VERSION ""

NS_ :

BS_:

BU_: VCU RMT AUTO

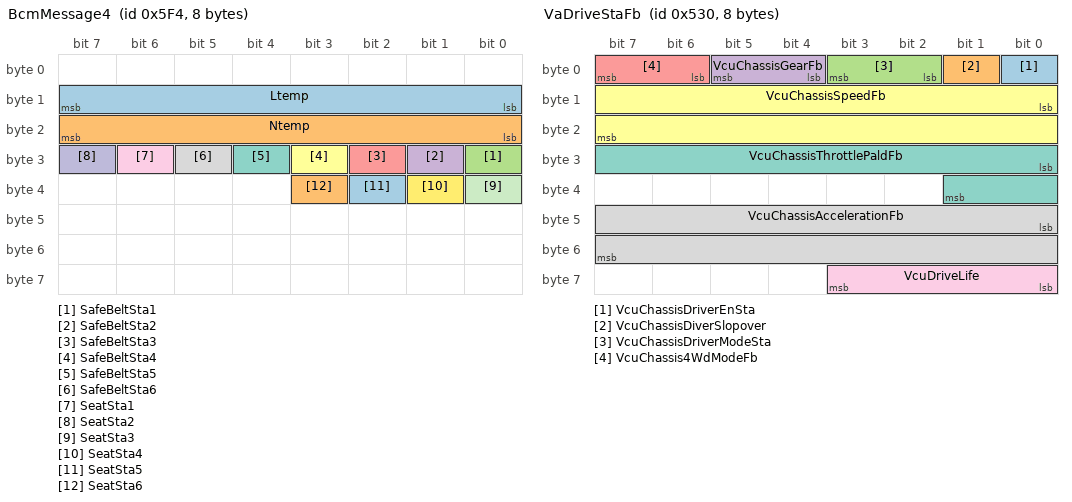
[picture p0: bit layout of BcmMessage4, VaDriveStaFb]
BO_ 1524 BcmMessage4: 8 VCU
 SG_ Ltemp : 8|8@1+ (1,-40) [-40|215] "℃"    RMT ,   AUTO
 SG_ Ntemp : 16|8@1+ (1,-40) [-40|215] "℃"    RMT ,   AUTO
 SG_ SafeBeltSta1 : 24|1@1+ (1,0) [0|1] ""    RMT ,   AUTO
 SG_ SafeBeltSta2 : 25|1@1+ (1,0) [0|1] ""    RMT ,   AUTO
 SG_ SafeBeltSta3 : 26|1@1+ (1,0) [0|1] ""    RMT ,   AUTO
 SG_ SafeBeltSta4 : 27|1@1+ (1,0) [0|1] ""    RMT ,   AUTO
 SG_ SafeBeltSta5 : 28|1@1+ (1,0) [0|1] ""    RMT ,   AUTO
 SG_ SafeBeltSta6 : 29|1@1+ (1,0) [0|1] ""    RMT ,   AUTO
 SG_ SeatSta1 : 30|1@1+ (1,0) [0|1] ""    RMT ,   AUTO
 SG_ SeatSta2 : 31|1@1+ (1,0) [0|1] ""    RMT ,   AUTO
 SG_ SeatSta3 : 32|1@1+ (1,0) [0|1] ""    RMT ,   AUTO
 SG_ SeatSta4 : 33|1@1+ (1,0) [0|1] ""    RMT ,   AUTO
 SG_ SeatSta5 : 34|1@1+ (1,0) [0|1] ""    RMT ,   AUTO
 SG_ SeatSta6 : 35|1@1+ (1,0) [0|1] ""    RMT ,   AUTO

BO_ 1525 BcmMessage5: 8 VCU
 SG_ AdVVin1 : 32|8@1+ (1,0) [0|255] ""    RMT ,   AUTO
 SG_ AdVVin2 : 40|8@1+ (1,0) [0|255] ""    RMT ,   AUTO

BO_ 1328 VaDriveStaFb: 8 VCU
 SG_ VcuChassisDriverEnSta : 0|1@1+ (1,0) [0|1] ""    RMT ,   AUTO
 SG_ VcuChassisDiverSlopover : 1|1@1+ (1,0) [0|1] ""    RMT ,   AUTO
 SG_ VcuChassisDriverModeSta : 2|2@1+ (1,0) [0|3] ""    RMT ,   AUTO
 SG_ VcuChassisGearFb : 4|2@1+ (1,0) [0|3] ""    RMT ,   AUTO
 SG_ VcuChassis4WdModeFb : 6|2@1+ (1,0) [0|2] ""    RMT ,   AUTO
 SG_ VcuChassisSpeedFb : 8|16@1- (0.01,0) [-50|50] "m/s"    RMT ,   AUTO
 SG_ VcuChassisThrottlePaldFb : 24|10@1+ (0.1,0) [0|100] "%"    RMT ,   AUTO
 SG_ VcuChassisAccelerationFb : 40|16@1- (0.01,0) [-20|20] "m/s2"    RMT ,   AUTO
 SG_ VcuDriveLife : 56|4@1+ (1,0) [0|15] ""    RMT ,   AUTO

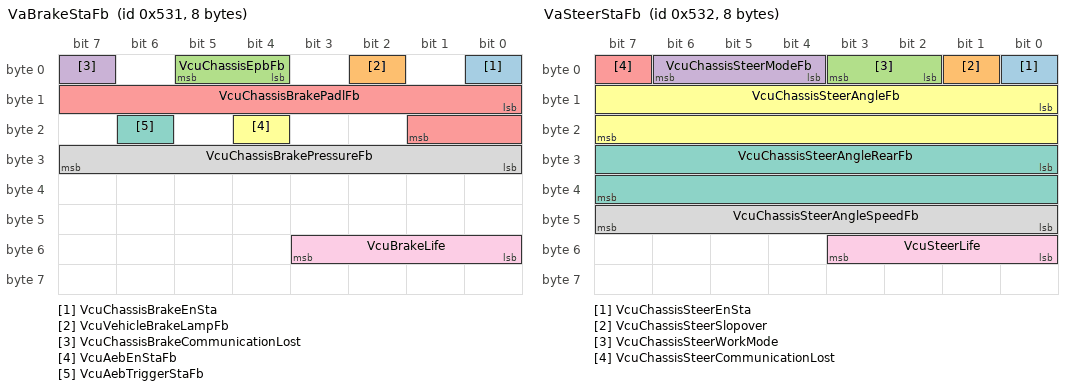
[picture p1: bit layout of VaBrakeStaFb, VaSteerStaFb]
BO_ 1329 VaBrakeStaFb: 8 VCU
 SG_ VcuChassisBrakeEnSta : 0|1@1+ (1,0) [0|1] ""    RMT ,   AUTO
 SG_ VcuVehicleBrakeLampFb : 2|1@1+ (1,0) [0|1] ""    RMT ,   AUTO
 SG_ VcuChassisEpbFb : 4|2@1+ (1,0) [0|3] ""    RMT ,   AUTO
 SG_ VcuChassisBrakeCommunicationLost : 7|1@1+ (1,0) [0|1] ""    RMT ,   AUTO
 SG_ VcuChassisBrakePadlFb : 8|10@1+ (0.1,0) [0|100] "%"    RMT ,   AUTO
 SG_ VcuAebEnStaFb : 20|1@1+ (1,0) [0|1] ""    RMT ,   AUTO
 SG_ VcuAebTriggerStaFb : 22|1@1+ (1,0) [0|1] ""    RMT ,   AUTO
 SG_ VcuChassisBrakePressureFb : 24|8@1+ (1,0) [0|100] "bar"    RMT ,   AUTO
 SG_ VcuBrakeLife : 48|4@1+ (1,0) [0|15] ""    RMT ,   AUTO

BO_ 1330 VaSteerStaFb: 8 VCU
 SG_ VcuChassisSteerEnSta : 0|1@1+ (1,0) [0|1] ""    RMT ,   AUTO
 SG_ VcuChassisSteerSlopover : 1|1@1+ (1,0) [0|1] ""    RMT ,   AUTO
 SG_ VcuChassisSteerWorkMode : 2|2@1+ (1,0) [0|2] ""    RMT ,   AUTO
 SG_ VcuChassisSteerModeFb : 4|3@1+ (1,0) [0|4] ""    RMT ,   AUTO
 SG_ VcuChassisSteerCommunicationLost : 7|1@1+ (1,0) [0|1] ""    RMT ,   AUTO
 SG_ VcuChassisSteerAngleFb : 8|16@1- (1,0) [-500|500] "deg"    RMT ,   AUTO
 SG_ VcuChassisSteerAngleRearFb : 24|16@1- (1,0) [-500|500] "deg"    RMT ,   AUTO
 SG_ VcuChassisSteerAngleSpeedFb : 40|8@1+ (2,0) [0|500] "deg/s"    RMT ,   AUTO
 SG_ VcuSteerLife : 48|4@1+ (1,0) [0|15] ""    RMT ,   AUTO

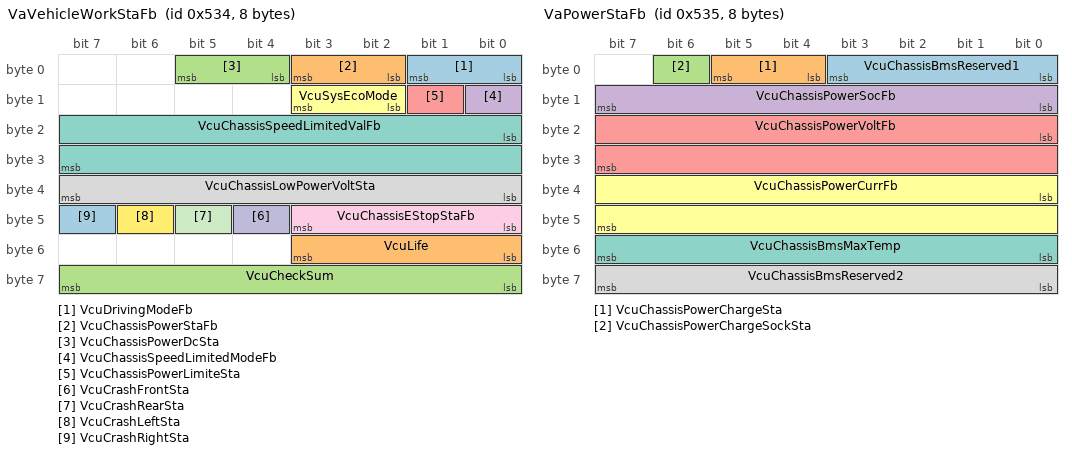
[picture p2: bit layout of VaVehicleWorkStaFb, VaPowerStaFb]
BO_ 1332 VaVehicleWorkStaFb: 8 VCU
 SG_ VcuDrivingModeFb : 0|2@1+ (1,0) [0|3] ""    RMT ,   AUTO
 SG_ VcuChassisPowerStaFb : 2|2@1+ (1,0) [0|3] ""    RMT ,   AUTO
 SG_ VcuChassisPowerDcSta : 4|2@1+ (1,0) [0|2] ""    RMT ,   AUTO
 SG_ VcuChassisSpeedLimitedModeFb : 8|1@1+ (1,0) [0|1] ""    RMT ,   AUTO
 SG_ VcuChassisPowerLimiteSta : 9|1@1+ (1,0) [0|1] ""    RMT ,   AUTO
 SG_ VcuSysEcoMode : 10|2@1+ (1,0) [0|2] ""    RMT ,   AUTO
 SG_ VcuChassisSpeedLimitedValFb : 16|16@1+ (0.1,0) [0|50] "m/s"    RMT ,   AUTO
 SG_ VcuChassisLowPowerVoltSta : 32|8@1+ (0.1,0) [0|25] "V"    RMT ,   AUTO
 SG_ VcuChassisEStopStaFb : 40|4@1+ (1,0) [0|3] ""    RMT ,   AUTO
 SG_ VcuCrashFrontSta : 44|1@1+ (1,0) [0|1] ""    RMT ,   AUTO
 SG_ VcuCrashRearSta : 45|1@1+ (1,0) [0|1] ""    RMT ,   AUTO
 SG_ VcuCrashLeftSta : 46|1@1+ (1,0) [0|1] ""    RMT ,   AUTO
 SG_ VcuCrashRightSta : 47|1@1+ (1,0) [0|1] ""    RMT ,   AUTO
 SG_ VcuLife : 48|4@1+ (1,0) [0|15] ""    RMT ,   AUTO
 SG_ VcuCheckSum : 56|8@1+ (1,0) [0|255] ""    RMT ,   AUTO

BO_ 1333 VaPowerStaFb: 8 VCU
 SG_ VcuChassisBmsReserved1 : 0|4@1+ (1,0) [0|15] ""    RMT ,   AUTO
 SG_ VcuChassisPowerChargeSta : 4|2@1+ (1,0) [0|2] ""    RMT ,   AUTO
 SG_ VcuChassisPowerChargeSockSta : 6|1@1+ (1,0) [0|1] ""    RMT ,   AUTO
 SG_ VcuChassisPowerSocFb : 8|8@1+ (1,0) [0|100] "%"    RMT ,   AUTO
 SG_ VcuChassisPowerVoltFb : 16|16@1+ (0.1,0) [0|1000] "V"    RMT ,   AUTO
 SG_ VcuChassisPowerCurrFb : 32|16@1+ (0.1,-1000) [-1000|1000] "A"    RMT ,   AUTO
 SG_ VcuChassisBmsMaxTemp : 48|8@1+ (1,-40) [-40|80] "℃"    RMT ,   AUTO
 SG_ VcuChassisBmsReserved2 : 56|8@1+ (1,0) [0|255] ""    RMT ,   AUTO

BO_ 1334 VaVehicleStaFb: 8 VCU
 SG_ VcuVehiclePosLampFb : 0|1@1+ (1,0) [0|1] ""    RMT ,   AUTO
 SG_ VcuVehicleHeadLampFb : 1|1@1+ (1,0) [0|1] ""    RMT ,   AUTO
 SG_ VcuVehicleLeftLampFb : 2|1@1+ (1,0) [0|1] ""    RMT ,   AUTO
 SG_ VcuVehicleRightLampFb : 3|1@1+ (1,0) [0|1] ""    RMT ,   AUTO
 SG_ VcuVehicleHighBeamFb : 4|1@1+ (1,0) [0|1] ""    RMT ,   AUTO
 SG_ VcuVehicleFogLampFb : 5|1@1+ (1,0) [0|1] ""    RMT ,   AUTO
 SG_ VcuVehicleHazardWarLampFb : 6|1@1+ (1,0) [0|1] ""    RMT ,   AUTO
 SG_ VcuVehicleBodyLampFb : 7|1@1+ (1,0) [0|1] ""    RMT ,   AUTO
 SG_ VcuVehicleReadLampFb : 8|1@1+ (1,0) [0|1] ""    RMT ,   AUTO
 SG_ AcuVehicleWindowFb : 9|4@1+ (1,0) [0|6] ""    RMT ,   AUTO
 SG_ VcuVehicleDoorStaFb : 16|4@1+ (1,0) [0|6] ""    RMT ,   AUTO
 SG_ VcuVehicleWipersStaFb : 20|2@1+ (1,0) [0|3] ""    RMT ,   AUTO
 SG_ VcuVehicleSafetyBelt1 : 24|2@1+ (1,0) [0|3] ""    RMT ,   AUTO
 SG_ VcuVehicleSafetyBelt2 : 26|2@1+ (1,0) [0|3] ""    RMT ,   AUTO
 SG_ VcuVehicleSafetyBelt3 : 28|2@1+ (1,0) [0|3] ""    RMT ,   AUTO
 SG_ VcuVehicleSafetyBelt4 : 30|2@1+ (1,0) [0|3] ""    RMT ,   AUTO
 SG_ VcuVehicleSafetyBelt5 : 32|2@1+ (1,0) [0|3] ""    AUTO
 SG_ VcuVehicleSafetyBelt6 : 34|2@1+ (1,0) [0|3] ""    AUTO
 SG_ VcuVehicleReserveWarning : 40|16@1+ (1,0) [0|65535] ""    AUTO
 SG_ VcuVehicleDisplaySpeed : 56|8@1+ (1,0) [0|240] "Km/h"    AUTO

BO_ 1335 VaVehicleFltSta: 8 VCU
 SG_ VcuSysMotorOverTempSta : 0|1@1+ (1,0) [0|1] ""    RMT ,   AUTO
 SG_ VcuSysBmsOverTempSta : 1|1@1+ (1,0) [0|1] ""    RMT ,   AUTO
 SG_ VcuSysBrakeOverTempSta : 2|1@1+ (1,0) [0|1] ""    RMT ,   AUTO
 SG_ VcuSysSteerOverTempSta : 3|1@1+ (1,0) [0|1] ""    RMT ,   AUTO
 SG_ VcuSysUnderVolt : 4|1@1+ (1,0) [0|1] ""    RMT ,   AUTO
 SG_ VcuSysFlt : 8|4@1+ (1,0) [0|4] ""    RMT ,   AUTO
 SG_ VcuSysBrakeFlt : 12|4@1+ (1,0) [0|4] ""    RMT ,   AUTO
 SG_ VcuSysParkingFlt : 16|4@1+ (1,0) [0|4] ""    RMT ,   AUTO
 SG_ VcuSysSteerFrontFlt : 20|4@1+ (1,0) [0|4] ""    RMT ,   AUTO
 SG_ VcuSysSteerBackFlt : 24|4@1+ (1,0) [0|4] ""    RMT ,   AUTO
 SG_ VcuSysMotorLfFlt : 28|4@1+ (1,0) [0|4] ""    RMT ,   AUTO
 SG_ VcuSysMotorRfFlt : 32|4@1+ (1,0) [0|4] ""    RMT ,   AUTO
 SG_ VcuSysMotorLrFlt : 36|4@1+ (1,0) [0|4] ""    RMT ,   AUTO
 SG_ VcuSysMotorRrFlt : 40|4@1+ (1,0) [0|4] ""    RMT ,   AUTO
 SG_ VcuSysBmsFlt : 44|4@1+ (1,0) [0|4] ""    RMT ,   AUTO
 SG_ VcuSysDcFlt : 48|2@1+ (1,0) [0|4] ""    RMT ,   AUTO
 SG_ VcuSysDoorFlt : 50|2@1+ (1,0) [0|3] ""    RMT ,   AUTO
 SG_ VcuSysDpmFlt : 52|2@1+ (1,0) [0|3] ""    RMT ,   AUTO
 SG_ VcuSysBcmFlt : 54|2@1+ (1,0) [0|3] ""    RMT ,   AUTO
 SG_ VcuVehicleFltLevel : 56|4@1+ (1,0) [0|4] ""    RMT ,   AUTO
 SG_ VcuSysFltReserve1 : 60|4@1+ (1,0) [0|4] ""    RMT ,   AUTO

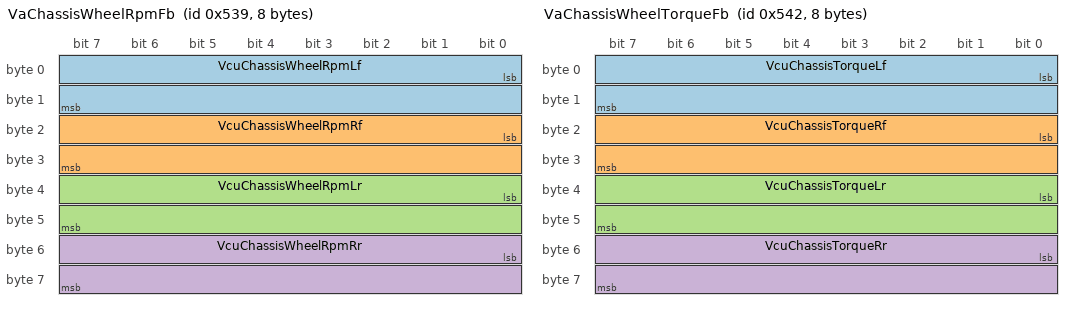
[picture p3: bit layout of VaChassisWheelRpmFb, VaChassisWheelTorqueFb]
BO_ 1337 VaChassisWheelRpmFb: 8 VCU
 SG_ VcuChassisWheelRpmLf : 0|16@1- (1,0) [-2000|2000] "rpm"    RMT ,   AUTO
 SG_ VcuChassisWheelRpmRf : 16|16@1- (1,0) [-2000|2000] "rpm"    RMT ,   AUTO
 SG_ VcuChassisWheelRpmLr : 32|16@1- (1,0) [-2000|2000] "rpm"    RMT ,   AUTO
 SG_ VcuChassisWheelRpmRr : 48|16@1- (1,0) [-2000|2000] "rpm"    RMT ,   AUTO

BO_ 1346 VaChassisWheelTorqueFb: 8 VCU
 SG_ VcuChassisTorqueLf : 0|16@1- (0.1,0) [-200|200] "Nm"    RMT ,   AUTO
 SG_ VcuChassisTorqueRf : 16|16@1- (0.1,0) [-200|200] "Nm"    RMT ,   AUTO
 SG_ VcuChassisTorqueLr : 32|16@1- (0.1,0) [-200|200] "Nm"    RMT ,   AUTO
 SG_ VcuChassisTorqueRr : 48|16@1- (0.1,0) [-200|200] "Nm"    RMT ,   AUTO

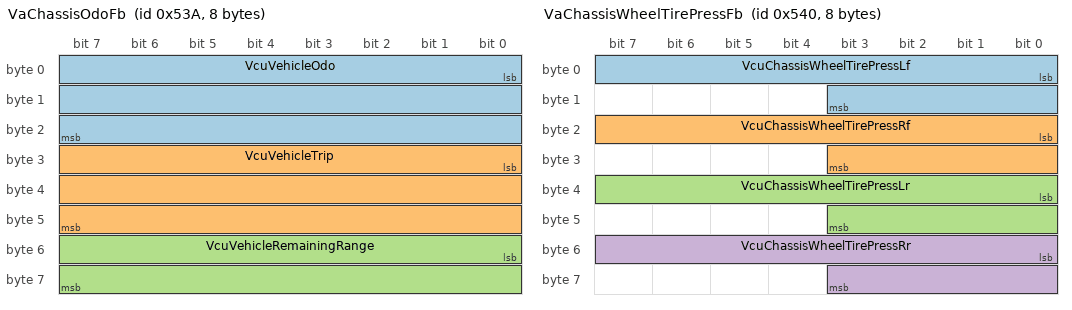
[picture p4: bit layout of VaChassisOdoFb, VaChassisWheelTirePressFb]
BO_ 1338 VaChassisOdoFb: 8 VCU
 SG_ VcuVehicleOdo : 0|24@1+ (1,0) [0|16777215] "km"    RMT ,   AUTO
 SG_ VcuVehicleTrip : 24|24@1+ (0.01,0) [0|167772.15] "km"    RMT ,   AUTO
 SG_ VcuVehicleRemainingRange : 48|16@1+ (1,0) [0|1000] "km"    RMT ,   AUTO

BO_ 1344 VaChassisWheelTirePressFb: 8 VCU
 SG_ VcuChassisWheelTirePressLf : 0|12@1+ (0.01,0) [0|20] "bar"    RMT ,   AUTO
 SG_ VcuChassisWheelTirePressRf : 16|12@1+ (0.01,0) [0|20] "bar"    RMT ,   AUTO
 SG_ VcuChassisWheelTirePressLr : 32|12@1+ (0.01,0) [0|20] "bar"    RMT ,   AUTO
 SG_ VcuChassisWheelTirePressRr : 48|12@1+ (0.01,0) [0|20] "bar"    RMT ,   AUTO

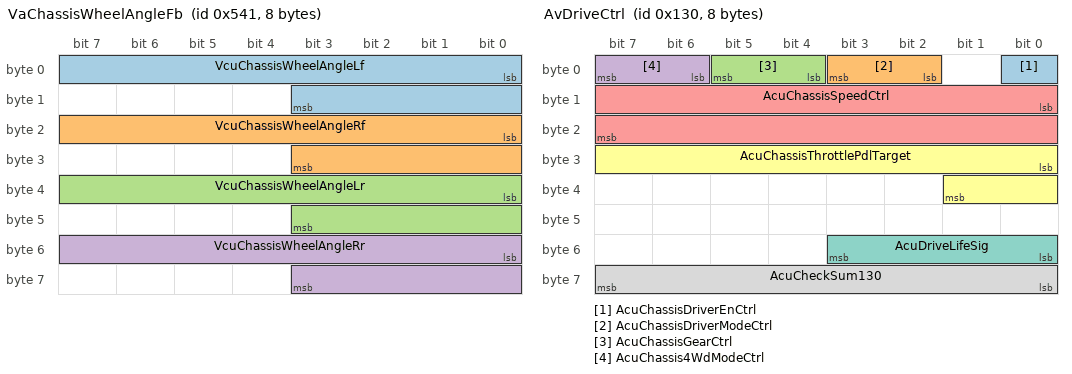
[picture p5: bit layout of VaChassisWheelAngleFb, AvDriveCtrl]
BO_ 1345 VaChassisWheelAngleFb: 8 VCU
 SG_ VcuChassisWheelAngleLf : 0|12@1- (0.1,0) [-90|90] "deg"    RMT ,   AUTO
 SG_ VcuChassisWheelAngleRf : 16|12@1- (0.1,0) [-90|90] "deg"    RMT ,   AUTO
 SG_ VcuChassisWheelAngleLr : 32|12@1- (0.1,0) [-90|90] "deg"    RMT ,   AUTO
 SG_ VcuChassisWheelAngleRr : 48|12@1- (0.1,0) [-90|90] "deg"    RMT ,   AUTO

BO_ 304 AvDriveCtrl: 8 RMT
 SG_ AcuChassisDriverEnCtrl : 0|1@1+ (1,0) [0|1] ""   VCU
 SG_ AcuChassisDriverModeCtrl : 2|2@1+ (1,0) [0|3] ""   VCU
 SG_ AcuChassisGearCtrl : 4|2@1+ (1,0) [0|3] ""   VCU
 SG_ AcuChassis4WdModeCtrl : 6|2@1+ (1,0) [0|2] ""   VCU
 SG_ AcuChassisSpeedCtrl : 8|16@1+ (0.01,0) [0|50] "m/s"   VCU
 SG_ AcuChassisThrottlePdlTarget : 24|10@1+ (0.1,0) [0|100] "%"   VCU
 SG_ AcuDriveLifeSig : 48|4@1+ (1,0) [0|15] ""   VCU
 SG_ AcuCheckSum130 : 56|8@1+ (1,0) [0|255] ""   VCU

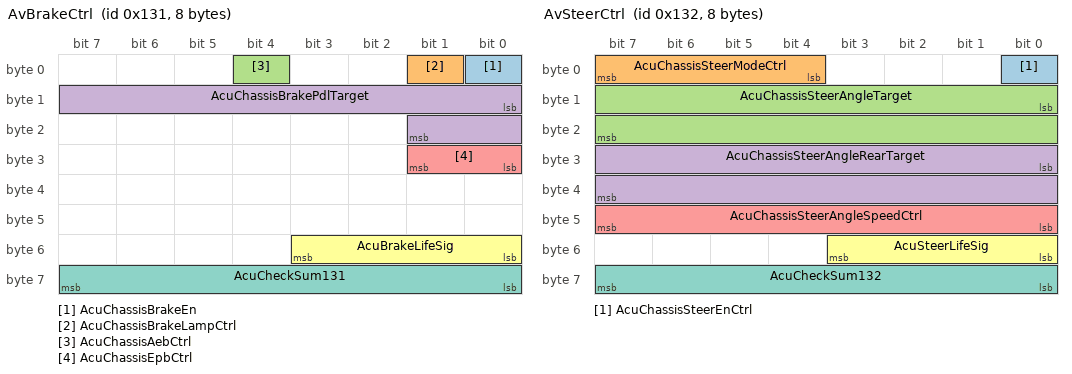
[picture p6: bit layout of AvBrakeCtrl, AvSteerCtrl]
BO_ 305 AvBrakeCtrl: 8 RMT
 SG_ AcuChassisBrakeEn : 0|1@1+ (1,0) [0|1] ""   VCU
 SG_ AcuChassisBrakeLampCtrl : 1|1@1+ (1,0) [0|1] ""   VCU
 SG_ AcuChassisAebCtrl : 4|1@1+ (1,0) [0|1] ""   VCU
 SG_ AcuChassisBrakePdlTarget : 8|10@1+ (0.1,0) [0|100] "%"   VCU
 SG_ AcuChassisEpbCtrl : 24|2@1+ (1,0) [0|2] ""   VCU
 SG_ AcuBrakeLifeSig : 48|4@1+ (1,0) [0|15] ""   VCU
 SG_ AcuCheckSum131 : 56|8@1+ (1,0) [0|255] ""   VCU

BO_ 306 AvSteerCtrl: 8 RMT
 SG_ AcuChassisSteerEnCtrl : 0|1@1+ (1,0) [0|1] ""   VCU
 SG_ AcuChassisSteerModeCtrl : 4|4@1+ (1,0) [0|4] ""   VCU
 SG_ AcuChassisSteerAngleTarget : 8|16@1- (1,0) [-500|500] "deg"   VCU
 SG_ AcuChassisSteerAngleRearTarget : 24|16@1- (1,0) [-500|500] "deg"   VCU
 SG_ AcuChassisSteerAngleSpeedCtrl : 40|8@1+ (2,0) [0|500] "deg/s"   VCU
 SG_ AcuSteerLifeSig : 48|4@1+ (1,0) [0|15] ""   VCU
 SG_ AcuCheckSum132 : 56|8@1+ (1,0) [0|255] ""   VCU

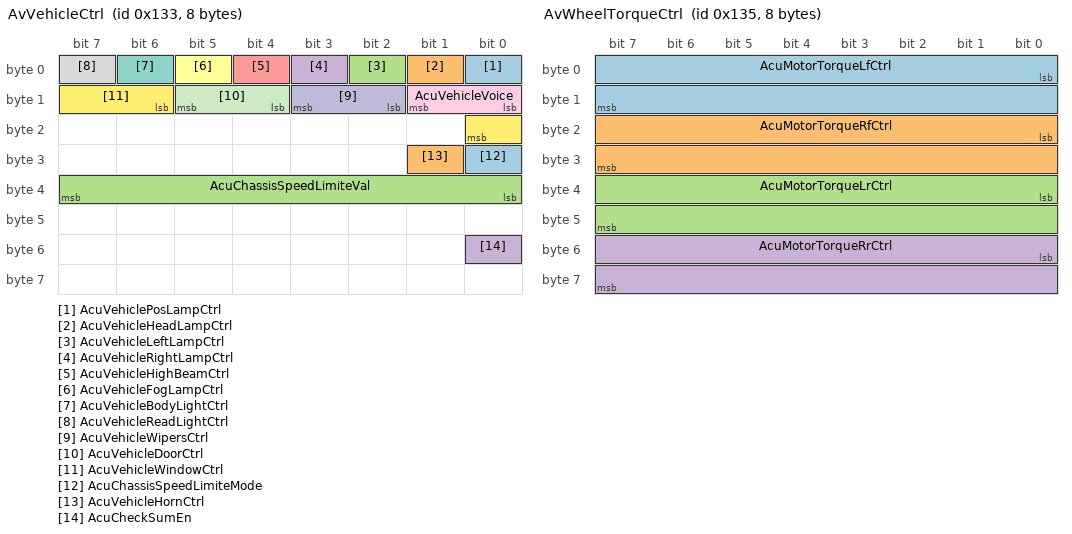
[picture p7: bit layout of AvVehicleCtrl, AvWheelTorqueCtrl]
BO_ 307 AvVehicleCtrl: 8 RMT
 SG_ AcuVehiclePosLampCtrl : 0|1@1+ (1,0) [0|1] ""   VCU
 SG_ AcuVehicleHeadLampCtrl : 1|1@1+ (1,0) [0|1] ""   VCU
 SG_ AcuVehicleLeftLampCtrl : 2|1@1+ (1,0) [0|1] ""   VCU
 SG_ AcuVehicleRightLampCtrl : 3|1@1+ (1,0) [0|1] ""   VCU
 SG_ AcuVehicleHighBeamCtrl : 4|1@1+ (1,0) [0|1] ""   VCU
 SG_ AcuVehicleFogLampCtrl : 5|1@1+ (1,0) [0|1] ""   VCU
 SG_ AcuVehicleBodyLightCtrl : 6|1@1+ (1,0) [0|1] ""   VCU
 SG_ AcuVehicleReadLightCtrl : 7|1@1+ (1,0) [0|1] ""   VCU
 SG_ AcuVehicleVoice : 8|2@1+ (1,0) [0|3] ""   VCU
 SG_ AcuVehicleWipersCtrl : 10|2@1+ (1,0) [0|3] ""   VCU
 SG_ AcuVehicleDoorCtrl : 12|2@1+ (1,0) [0|2] ""   VCU
 SG_ AcuVehicleWindowCtrl : 14|3@1+ (1,0) [0|2] ""   VCU
 SG_ AcuChassisSpeedLimiteMode : 24|1@1+ (1,0) [0|1] ""   VCU
 SG_ AcuVehicleHornCtrl : 25|1@1+ (1,0) [0|1] ""   VCU
 SG_ AcuChassisSpeedLimiteVal : 32|8@1+ (0.1,0) [1|20] "m/s"   VCU
 SG_ AcuCheckSumEn : 48|1@1+ (1,0) [0|1] ""   VCU

BO_ 309 AvWheelTorqueCtrl: 8 RMT
 SG_ AcuMotorTorqueLfCtrl : 0|16@1- (0.1,0) [-200|200] "Nm"   VCU
 SG_ AcuMotorTorqueRfCtrl : 16|16@1- (0.1,0) [-200|200] "Nm"   VCU
 SG_ AcuMotorTorqueLrCtrl : 32|16@1- (0.1,0) [-200|200] "Nm"   VCU
 SG_ AcuMotorTorqueRrCtrl : 48|16@1- (0.1,0) [-200|200] "Nm"   VCU

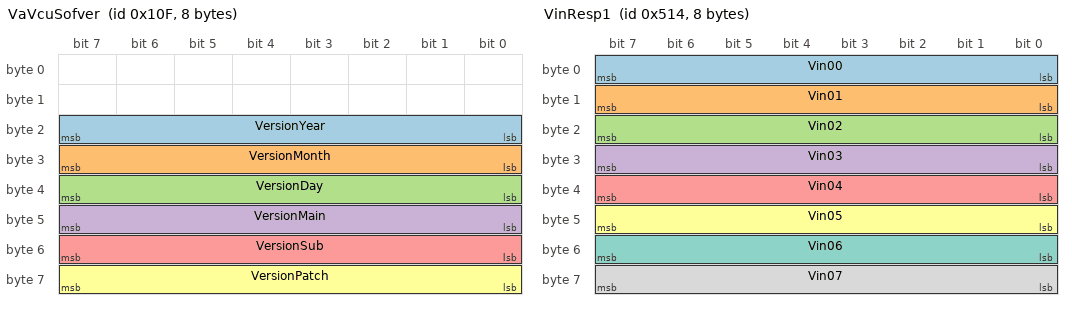
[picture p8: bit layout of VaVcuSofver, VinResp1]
BO_ 271 VaVcuSofver: 8 VCU
 SG_ VersionYear : 16|8@1+ (1,0) [0|255] ""    RMT ,   AUTO
 SG_ VersionMonth : 24|8@1+ (1,0) [0|255] ""    RMT ,   AUTO
 SG_ VersionDay : 32|8@1+ (1,0) [0|255] ""    RMT ,   AUTO
 SG_ VersionMain : 40|8@1+ (1,0) [0|255] ""    RMT ,   AUTO
 SG_ VersionSub : 48|8@1+ (1,0) [0|255] ""    RMT ,   AUTO
 SG_ VersionPatch : 56|8@1+ (1,0) [0|255] ""    RMT ,   AUTO

BO_ 1300 VinResp1: 8 VCU
 SG_ Vin00 : 0|8@1+ (1,0) [0|255] ""    RMT ,   AUTO
 SG_ Vin01 : 8|8@1+ (1,0) [0|255] ""    RMT ,   AUTO
 SG_ Vin02 : 16|8@1+ (1,0) [0|255] ""    RMT ,   AUTO
 SG_ Vin03 : 24|8@1+ (1,0) [0|255] ""    RMT ,   AUTO
 SG_ Vin04 : 32|8@1+ (1,0) [0|255] ""    RMT ,   AUTO
 SG_ Vin05 : 40|8@1+ (1,0) [0|255] ""    RMT ,   AUTO
 SG_ Vin06 : 48|8@1+ (1,0) [0|255] ""    RMT ,   AUTO
 SG_ Vin07 : 56|8@1+ (1,0) [0|255] ""    RMT ,   AUTO

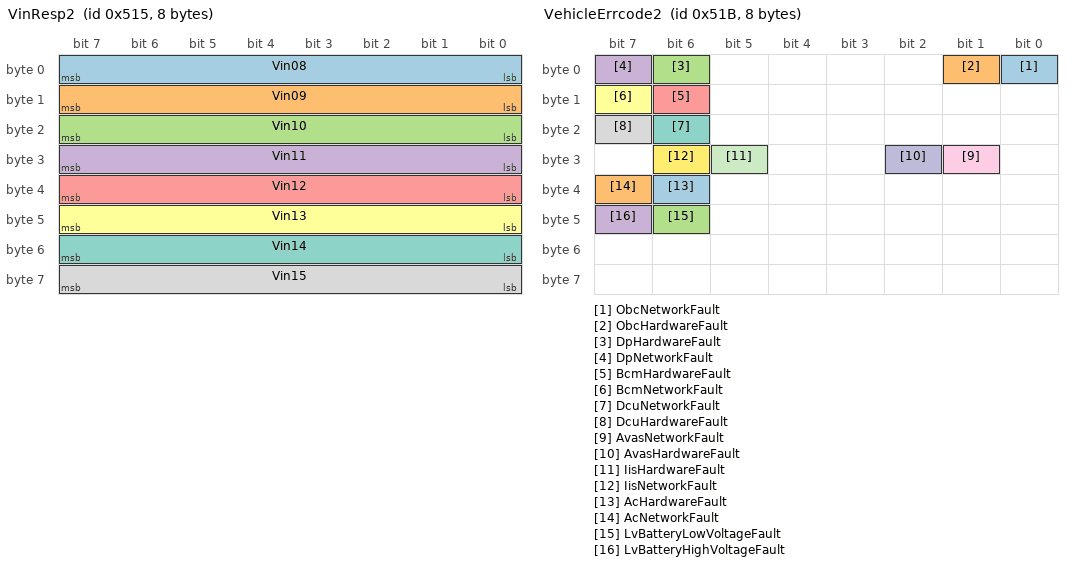
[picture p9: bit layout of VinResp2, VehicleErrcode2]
BO_ 1301 VinResp2: 8 VCU
 SG_ Vin08 : 0|8@1+ (1,0) [0|255] ""    RMT ,   AUTO
 SG_ Vin09 : 8|8@1+ (1,0) [0|255] ""    RMT ,   AUTO
 SG_ Vin10 : 16|8@1+ (1,0) [0|255] ""    RMT ,   AUTO
 SG_ Vin11 : 24|8@1+ (1,0) [0|255] ""    RMT ,   AUTO
 SG_ Vin12 : 32|8@1+ (1,0) [0|255] ""    RMT ,   AUTO
 SG_ Vin13 : 40|8@1+ (1,0) [0|255] ""    RMT ,   AUTO
 SG_ Vin14 : 48|8@1+ (1,0) [0|255] ""    RMT ,   AUTO
 SG_ Vin15 : 56|8@1+ (1,0) [0|255] ""    RMT ,   AUTO

BO_ 1302 VinResp3: 8 VCU
 SG_ Vin16 : 0|8@1+ (1,0) [0|255] ""    RMT ,   AUTO

BO_ 928 AutoMessage: 8 RMT
 SG_ AutoDriveMode : 0|8@1+ (1,0) [0|255] ""    VCU ,   AUTO
 SG_ AutoHeartbeat : 56|8@1+ (1,0) [0|255] ""    VCU ,   AUTO

BO_ 944 RemoteMessage: 8 AUTO
 SG_ RemoteDriveMode : 0|8@1+ (1,0) [0|255] ""   VCU,  RMT
 SG_ RemoteHeartbeat : 56|8@1+ (1,0) [0|255] ""   VCU,  RMT

BO_ 1339 VcuTransfer: 8 VCU
 SG_ AcOutTemp : 40|8@1- (1,-40) [-40|215] "℃"    RMT ,   AUTO
 SG_ AcInTemp : 48|8@1- (1,-40) [-40|215] "℃"    RMT ,   AUTO

BO_ 1306 VehicleErrcode1: 8 VCU
 SG_ FlmcHardwareFault : 0|1@1+ (1,0) [0|1] ""    RMT ,   AUTO
 SG_ FlmcTemFault : 1|1@1+ (1,0) [0|1] ""    RMT ,   AUTO
 SG_ FlmTemFault : 2|1@1+ (1,0) [0|1] ""    RMT ,   AUTO
 SG_ RlmcHardwareFault : 3|1@1+ (1,0) [0|1] ""    RMT ,   AUTO
 SG_ RlmcTemFault : 4|1@1+ (1,0) [0|1] ""    RMT ,   AUTO
 SG_ RlmTemFault : 5|1@1+ (1,0) [0|1] ""    RMT ,   AUTO
 SG_ FrmcHardwareFault : 6|1@1+ (1,0) [0|1] ""    RMT ,   AUTO
 SG_ FrmcTemFault : 7|1@1+ (1,0) [0|1] ""    RMT ,   AUTO
 SG_ FrmTemFault : 8|1@1+ (1,0) [0|1] ""    RMT ,   AUTO
 SG_ RrmcHardwareFault : 9|1@1+ (1,0) [0|1] ""    RMT ,   AUTO
 SG_ RrmcTemFault : 10|1@1+ (1,0) [0|1] ""    RMT ,   AUTO
 SG_ RrmTemFault : 11|1@1+ (1,0) [0|1] ""    RMT ,   AUTO
 SG_ FlmcNetworkFault : 12|1@1+ (1,0) [0|1] ""    RMT ,   AUTO
 SG_ FrmcNetworkFault : 13|1@1+ (1,0) [0|1] ""    RMT ,   AUTO
 SG_ RlmcNetworkFault : 14|1@1+ (1,0) [0|1] ""    RMT ,   AUTO
 SG_ RrmcNetworkFault : 15|1@1+ (1,0) [0|1] ""    RMT ,   AUTO
 SG_ FsteerHardwareFault : 16|1@1+ (1,0) [0|1] ""    RMT ,   AUTO
 SG_ RsteerHardwareFault : 17|1@1+ (1,0) [0|1] ""    RMT ,   AUTO
 SG_ FsteerNetworkFault : 18|1@1+ (1,0) [0|1] ""    RMT ,   AUTO
 SG_ RsteerNetworkFault : 19|1@1+ (1,0) [0|1] ""    RMT ,   AUTO
 SG_ BrakeHardwareFault : 20|1@1+ (1,0) [0|1] ""    RMT ,   AUTO
 SG_ BrakeHighTemFault : 21|1@1+ (1,0) [0|1] ""    RMT ,   AUTO
 SG_ BrakeLuidLevelLow : 22|1@1+ (1,0) [0|1] ""    RMT ,   AUTO
 SG_ BrakeNetworkFault : 23|1@1+ (1,0) [0|1] ""    RMT ,   AUTO
 SG_ ParkHardwareFault : 24|1@1+ (1,0) [0|1] ""    RMT ,   AUTO
 SG_ ParkNetworkFault : 25|1@1+ (1,0) [0|1] ""    RMT ,   AUTO
 SG_ RcuNetworkFault : 26|1@1+ (1,0) [0|1] ""    RMT ,   AUTO
 SG_ RcuWeakSignal : 27|1@1+ (1,0) [0|1] ""    RMT ,   AUTO
 SG_ RcuElecLowAlarm : 28|1@1+ (1,0) [0|1] ""    RMT ,   AUTO
 SG_ BmsNetworkFault : 31|1@1+ (1,0) [0|1] ""    RMT ,   AUTO
 SG_ BmsInsulationfault : 32|1@1+ (1,0) [0|1] ""    RMT ,   AUTO
 SG_ BmsOcvCell : 33|1@1+ (1,0) [0|1] ""    RMT ,   AUTO
 SG_ BmsOdvCell : 34|1@1+ (1,0) [0|1] ""    RMT ,   AUTO
 SG_ BmsOcvBatt : 35|1@1+ (1,0) [0|1] ""    RMT ,   AUTO
 SG_ BmsOdvBatt : 36|1@1+ (1,0) [0|1] ""    RMT ,   AUTO
 SG_ BmsCellVoltDiff : 37|1@1+ (1,0) [0|1] ""    RMT ,   AUTO
 SG_ BmsTemph : 38|1@1+ (1,0) [0|1] ""    RMT ,   AUTO
 SG_ BmsTemphl : 39|1@1+ (1,0) [0|1] ""    RMT ,   AUTO
 SG_ BmsTemphDiff : 40|1@1+ (1,0) [0|1] ""    RMT ,   AUTO
 SG_ BmsWarchgOvercurrent : 41|1@1+ (1,0) [0|1] ""    RMT ,   AUTO
 SG_ BmsSoch : 42|1@1+ (1,0) [0|1] ""    RMT ,   AUTO
 SG_ BmsSocl : 43|1@1+ (1,0) [0|1] ""    RMT ,   AUTO
 SG_ BmsTimeOfHeatingTooLong : 44|1@1+ (1,0) [0|1] ""    RMT ,   AUTO
 SG_ BmsSocBreak : 45|1@1+ (1,0) [0|1] ""    RMT ,   AUTO
 SG_ BmsDisCharOverCur : 46|1@1+ (1,0) [0|1] ""    RMT ,   AUTO
 SG_ BmsCharOverCurSlow : 47|1@1+ (1,0) [0|1] ""    RMT ,   AUTO
 SG_ BmsfastCharOverCur : 48|1@1+ (1,0) [0|1] ""    RMT ,   AUTO
 SG_ BmsAlmSenseCell : 49|1@1+ (1,0) [0|1] ""    RMT ,   AUTO
 SG_ BmsAlmSenseTemp : 50|1@1+ (1,0) [0|1] ""    RMT ,   AUTO
 SG_ BmsAlmSenseCurr : 51|1@1+ (1,0) [0|1] ""    RMT ,   AUTO
 SG_ BmsHvil : 52|1@1+ (1,0) [0|1] ""    RMT ,   AUTO
 SG_ BmsWarIncanFault : 53|1@1+ (1,0) [0|1] ""    RMT ,   AUTO
 SG_ BmsLstComWithobc : 54|1@1+ (1,0) [0|1] ""    RMT ,   AUTO
 SG_ BmsLstComWithVcu : 55|1@1+ (1,0) [0|1] ""    RMT ,   AUTO
 SG_ BmsPrechargerFault : 56|1@1+ (1,0) [0|1] ""    RMT ,   AUTO
 SG_ BmsposRelayconglutination : 57|1@1+ (1,0) [0|1] ""    RMT ,   AUTO
 SG_ BmsNegRelayConglutination : 58|1@1+ (1,0) [0|1] ""    RMT ,   AUTO
 SG_ DcdcHighTemAlarm : 61|1@1+ (1,0) [0|1] "" Vector__XXX
 SG_ DcdcHardwareFault : 62|1@1+ (1,0) [0|1] ""    RMT ,   AUTO
 SG_ DcdcNetworkFault : 63|1@1+ (1,0) [0|1] ""    RMT ,   AUTO

BO_ 1307 VehicleErrcode2: 8 VCU
 SG_ ObcNetworkFault : 0|1@1+ (1,0) [0|1] ""    RMT ,   AUTO
 SG_ ObcHardwareFault : 1|1@1+ (1,0) [0|1] ""    RMT ,   AUTO
 SG_ DpHardwareFault : 6|1@1+ (1,0) [0|1] ""    RMT ,   AUTO
 SG_ DpNetworkFault : 7|1@1+ (1,0) [0|1] ""    RMT ,   AUTO
 SG_ BcmHardwareFault : 14|1@1+ (1,0) [0|1] ""    RMT ,   AUTO
 SG_ BcmNetworkFault : 15|1@1+ (1,0) [0|1] ""    RMT ,   AUTO
 SG_ DcuNetworkFault : 22|1@1+ (1,0) [0|1] ""    RMT ,   AUTO
 SG_ DcuHardwareFault : 23|1@1+ (1,0) [0|1] ""    RMT ,   AUTO
 SG_ AvasNetworkFault : 25|1@1+ (1,0) [0|1] ""    RMT ,   AUTO
 SG_ AvasHardwareFault : 26|1@1+ (1,0) [0|1] ""    RMT ,   AUTO
 SG_ IisHardwareFault : 29|1@1+ (1,0) [0|1] ""    RMT ,   AUTO
 SG_ IisNetworkFault : 30|1@1+ (1,0) [0|1] ""    RMT ,   AUTO
 SG_ AcHardwareFault : 38|1@1+ (1,0) [0|1] ""    RMT ,   AUTO
 SG_ AcNetworkFault : 39|1@1+ (1,0) [0|1] ""    RMT ,   AUTO
 SG_ LvBatteryLowVoltageFault : 46|1@1+ (1,0) [0|1] ""    RMT ,   AUTO
 SG_ LvBatteryHighVoltageFault : 47|1@1+ (1,0) [0|1] ""    RMT ,   AUTO

BO_ 1308 HistoricalVehiclefailures1: 8 VCU
 SG_ FlmcHardwareFault : 0|1@1+ (1,0) [0|1] ""    RMT ,   AUTO
 SG_ FlmcTemFault : 1|1@1+ (1,0) [0|1] ""    RMT ,   AUTO
 SG_ FlmTemFault : 2|1@1+ (1,0) [0|1] ""    RMT ,   AUTO
 SG_ RlmcHardwareFault : 3|1@1+ (1,0) [0|1] ""    RMT ,   AUTO
 SG_ RlmcTemFault : 4|1@1+ (1,0) [0|1] ""    RMT ,   AUTO
 SG_ RlmTemFault : 5|1@1+ (1,0) [0|1] ""    RMT ,   AUTO
 SG_ FrmcHardwareFault : 6|1@1+ (1,0) [0|1] ""    RMT ,   AUTO
 SG_ FrmcTemFault : 7|1@1+ (1,0) [0|1] ""    RMT ,   AUTO
 SG_ FrmTemFault : 8|1@1+ (1,0) [0|1] ""    RMT ,   AUTO
 SG_ RrmcHardwareFault : 9|1@1+ (1,0) [0|1] ""    RMT ,   AUTO
 SG_ RrmcTemFault : 10|1@1+ (1,0) [0|1] ""    RMT ,   AUTO
 SG_ RrmTemFault : 11|1@1+ (1,0) [0|1] ""    RMT ,   AUTO
 SG_ FlmcNetworkFault : 12|1@1+ (1,0) [0|1] ""    RMT ,   AUTO
 SG_ FrmcNetworkFault : 13|1@1+ (1,0) [0|1] ""    RMT ,   AUTO
 SG_ RlmcNetworkFault : 14|1@1+ (1,0) [0|1] ""    RMT ,   AUTO
 SG_ RrmcNetworkFault : 15|1@1+ (1,0) [0|1] ""    RMT ,   AUTO
 SG_ FsteerHardwareFault : 16|1@1+ (1,0) [0|1] ""    RMT ,   AUTO
 SG_ RsteerHardwareFault : 17|1@1+ (1,0) [0|1] ""    RMT ,   AUTO
 SG_ FsteerNetworkFault : 18|1@1+ (1,0) [0|1] ""    RMT ,   AUTO
 SG_ RsteerNetworkFault : 19|1@1+ (1,0) [0|1] ""    RMT ,   AUTO
 SG_ BrakeHardwareFault : 20|1@1+ (1,0) [0|1] ""    RMT ,   AUTO
 SG_ BrakeHighTemFault : 21|1@1+ (1,0) [0|1] ""    RMT ,   AUTO
 SG_ BrakeLuidLevelLow : 22|1@1+ (1,0) [0|1] ""    RMT ,   AUTO
 SG_ BrakeNetworkFault : 23|1@1+ (1,0) [0|1] ""    RMT ,   AUTO
 SG_ ParkHardwareFault : 24|1@1+ (1,0) [0|1] ""    RMT ,   AUTO
 SG_ ParkNetworkFault : 25|1@1+ (1,0) [0|1] ""    RMT ,   AUTO
 SG_ RcuNetworkFault : 26|1@1+ (1,0) [0|1] ""    RMT ,   AUTO
 SG_ RcuWeakSignal : 27|1@1+ (1,0) [0|1] ""    RMT ,   AUTO
 SG_ RcuElecLowAlarm : 28|1@1+ (1,0) [0|1] ""    RMT ,   AUTO
 SG_ BmsNetworkFault : 31|1@1+ (1,0) [0|1] ""    RMT ,   AUTO
 SG_ BmsInsulationfault : 32|1@1+ (1,0) [0|1] ""    RMT ,   AUTO
 SG_ BmsOcvCell : 33|1@1+ (1,0) [0|1] ""    RMT ,   AUTO
 SG_ BmsOdvCell : 34|1@1+ (1,0) [0|1] ""    RMT ,   AUTO
 SG_ BmsOcvBatt : 35|1@1+ (1,0) [0|1] ""    RMT ,   AUTO
 SG_ BmsOdvBatt : 36|1@1+ (1,0) [0|1] ""    RMT ,   AUTO
 SG_ BmsCellVoltDiff : 37|1@1+ (1,0) [0|1] ""    RMT ,   AUTO
 SG_ BmsTemph : 38|1@1+ (1,0) [0|1] ""    RMT ,   AUTO
 SG_ BmsTemphl : 39|1@1+ (1,0) [0|1] ""    RMT ,   AUTO
 SG_ BmsTemphDiff : 40|1@1+ (1,0) [0|1] ""    RMT ,   AUTO
 SG_ BmsWarchgOvercurrent : 41|1@1+ (1,0) [0|1] ""    RMT ,   AUTO
 SG_ BmsSoch : 42|1@1+ (1,0) [0|1] ""    RMT ,   AUTO
 SG_ BmsSocl : 43|1@1+ (1,0) [0|1] ""    RMT ,   AUTO
 SG_ BmsTimeOfHeatingTooLong : 44|1@1+ (1,0) [0|1] ""    RMT ,   AUTO
 SG_ BmsSocBreak : 45|1@1+ (1,0) [0|1] ""    RMT ,   AUTO
 SG_ BmsDisCharOverCur : 46|1@1+ (1,0) [0|1] ""    RMT ,   AUTO
 SG_ BmsCharOverCurSlow : 47|1@1+ (1,0) [0|1] ""    RMT ,   AUTO
 SG_ BmsfastCharOverCur : 48|1@1+ (1,0) [0|1] ""    RMT ,   AUTO
 SG_ BmsAlmSenseCell : 49|1@1+ (1,0) [0|1] ""    RMT ,   AUTO
 SG_ BmsAlmSenseTemp : 50|1@1+ (1,0) [0|1] ""    RMT ,   AUTO
 SG_ BmsAlmSenseCurr : 51|1@1+ (1,0) [0|1] ""    RMT ,   AUTO
 SG_ BmsHvil : 52|1@1+ (1,0) [0|1] ""    RMT ,   AUTO
 SG_ BmsWarIncanFault : 53|1@1+ (1,0) [0|1] ""    RMT ,   AUTO
 SG_ BmsLstComWithobc : 54|1@1+ (1,0) [0|1] ""    RMT ,   AUTO
 SG_ BmsLstComWithVcu : 55|1@1+ (1,0) [0|1] ""    RMT ,   AUTO
 SG_ BmsPrechargerFault : 56|1@1+ (1,0) [0|1] ""    RMT ,   AUTO
 SG_ BmsposRelayconglutination : 57|1@1+ (1,0) [0|1] ""    RMT ,   AUTO
 SG_ BmsNegRelayConglutination : 58|1@1+ (1,0) [0|1] ""    RMT ,   AUTO
 SG_ DcdcHighTemAlarm : 61|1@1+ (1,0) [0|1] ""    RMT ,   AUTO
 SG_ DcdcHardwareFault : 62|1@1+ (1,0) [0|1] ""    RMT ,   AUTO
 SG_ DcdcNetworkFault : 63|1@1+ (1,0) [0|1] ""    RMT ,   AUTO

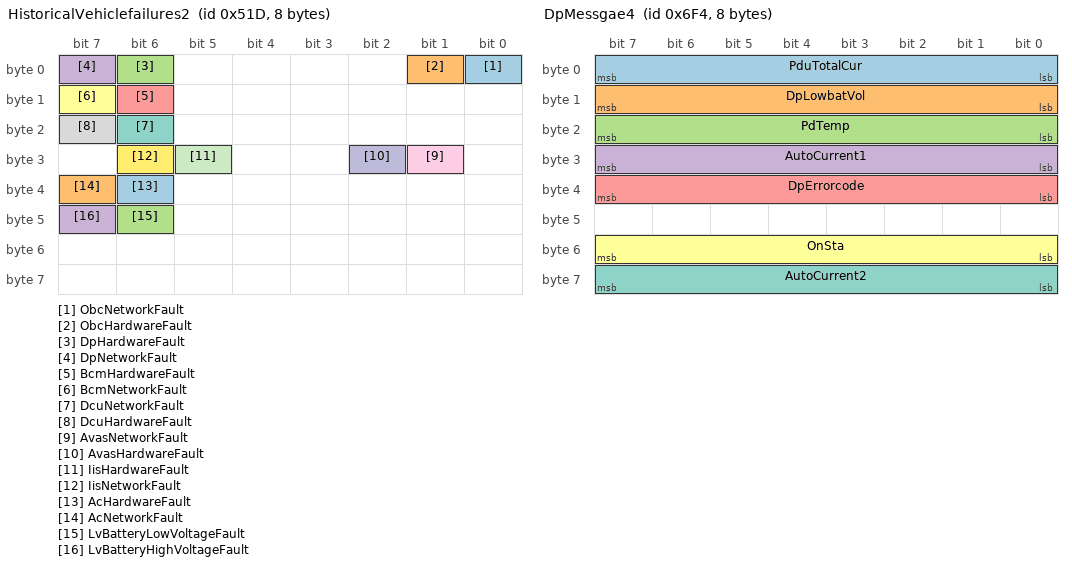
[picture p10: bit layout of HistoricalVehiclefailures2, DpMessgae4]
BO_ 1309 HistoricalVehiclefailures2: 8 VCU
 SG_ ObcNetworkFault : 0|1@1+ (1,0) [0|1] ""    RMT ,   AUTO
 SG_ ObcHardwareFault : 1|1@1+ (1,0) [0|1] ""    RMT ,   AUTO
 SG_ DpHardwareFault : 6|1@1+ (1,0) [0|1] ""    RMT ,   AUTO
 SG_ DpNetworkFault : 7|1@1+ (1,0) [0|1] ""    RMT ,   AUTO
 SG_ BcmHardwareFault : 14|1@1+ (1,0) [0|1] ""    RMT ,   AUTO
 SG_ BcmNetworkFault : 15|1@1+ (1,0) [0|1] ""    RMT ,   AUTO
 SG_ DcuNetworkFault : 22|1@1+ (1,0) [0|1] ""    RMT ,   AUTO
 SG_ DcuHardwareFault : 23|1@1+ (1,0) [0|1] ""    RMT ,   AUTO
 SG_ AvasNetworkFault : 25|1@1+ (1,0) [0|1] ""    RMT ,   AUTO
 SG_ AvasHardwareFault : 26|1@1+ (1,0) [0|1] ""    RMT ,   AUTO
 SG_ IisHardwareFault : 29|1@1+ (1,0) [0|1] ""    RMT ,   AUTO
 SG_ IisNetworkFault : 30|1@1+ (1,0) [0|1] ""    RMT ,   AUTO
 SG_ AcHardwareFault : 38|1@1+ (1,0) [0|1] ""    RMT ,   AUTO
 SG_ AcNetworkFault : 39|1@1+ (1,0) [0|1] ""    RMT ,   AUTO
 SG_ LvBatteryLowVoltageFault : 46|1@1+ (1,0) [0|1] ""    RMT ,   AUTO
 SG_ LvBatteryHighVoltageFault : 47|1@1+ (1,0) [0|1] ""    RMT ,   AUTO

BO_ 1780 DpMessgae4: 8 VCU
 SG_ PduTotalCur : 0|8@1+ (1,0) [0|255] "A"    RMT ,   AUTO
 SG_ DpLowbatVol : 8|8@1+ (0.5,0) [0|127.5] "V"    RMT ,   AUTO
 SG_ PdTemp : 16|8@1+ (1,-40) [-40|215] "℃"    RMT ,   AUTO
 SG_ AutoCurrent1 : 24|8@1+ (1,0) [0|255] "A"    RMT ,   AUTO
 SG_ DpErrorcode : 32|8@1+ (1,0) [0|255] ""    RMT ,   AUTO
 SG_ OnSta : 48|8@1+ (1,0) [0|255] ""    RMT ,   AUTO
 SG_ AutoCurrent2 : 56|8@1+ (1,0) [0|255] "A"    RMT ,   AUTO
